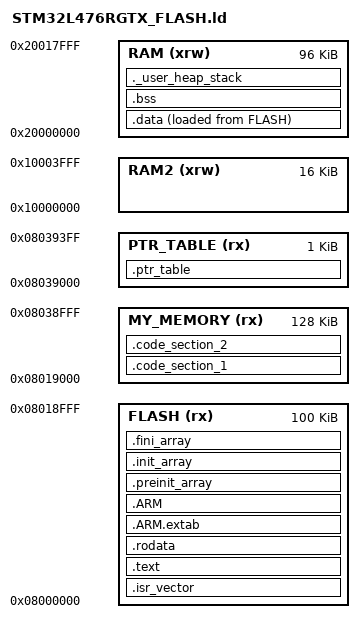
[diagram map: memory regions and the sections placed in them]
/*
******************************************************************************
**
** @file        : LinkerScript.ld
**
** @author      : Auto-generated by STM32CubeIDE
**
**  Abstract    : Linker script for NUCLEO-L476RG Board embedding STM32L476RGTx Device from stm32l4 series
**                      1024Kbytes FLASH
**                      96Kbytes RAM
**                      32Kbytes RAM2
**
**                Set heap size, stack size and stack location according
**                to application requirements.
**
**                Set memory bank area and size if external memory is used
**
**  Target      : STMicroelectronics STM32
**
**  Distribution: The file is distributed as is, without any warranty
**                of any kind.
**
******************************************************************************
** @attention
**
** Copyright (c) 2022 STMicroelectronics.
** All rights reserved.
**
** This software is licensed under terms that can be found in the LICENSE file
** in the root directory of this software component.
** If no LICENSE file comes with this software, it is provided AS-IS.
**
******************************************************************************
*/

/* Entry Point */
ENTRY(Reset_Handler)

/* Highest address of the user mode stack */
_estack = ORIGIN(RAM) + LENGTH(RAM); /* end of "RAM" Ram type memory */

_Min_Heap_Size = 0x200 ; /* required amount of heap */
_Min_Stack_Size = 0x400 ; /* required amount of stack */

/* Memories definition */
MEMORY
{
  RAM    (xrw)    	: ORIGIN = 0x20000000,  LENGTH = 96K
  RAM2    (xrw)    	: ORIGIN = 0x10000000,  LENGTH = 16K
  FLASH    (rx)    	: ORIGIN = 0x8000000,   LENGTH = 100K
  MY_MEMORY (rx)  	: ORIGIN = 0x8019000,	LENGTH = 128k
  PTR_TABLE (rx)  	: ORIGIN = 0x8039000,	LENGTH = 1k
}

/* Sections */
SECTIONS
{
  /* The startup code into "FLASH" Rom type memory */
  .isr_vector :
  {
    . = ALIGN(4);
    KEEP(*(.isr_vector)) /* Startup code */
    . = ALIGN(4);
  } >FLASH

  /* The program code and other data into "FLASH" Rom type memory */
  .text :
  {
    . = ALIGN(4);
    *(.text)           /* .text sections (code) */
    *(.text*)          /* .text* sections (code) */
    *(.glue_7)         /* glue arm to thumb code */
    *(.glue_7t)        /* glue thumb to arm code */
    *(.eh_frame)

    KEEP (*(.init))
    KEEP (*(.fini))

    . = ALIGN(4);
    _etext = .;        /* define a global symbols at end of code */
  } >FLASH
  
    /* LUT for function pointers */
  .ptr_table :
  {
  	__ptr_table_start__ = .;
	. = ALIGN(4);
	lut_func_ptr_1 = .;
	lut_func_ptr_2 = .;
	lut_func_ptr_3 = .;
	lut_func_ptr_4 = .;
	. = ALIGN(4);
  	__ptr_table_end__ = .;
  } >PTR_TABLE

  /* Check if PTR_TABLE usage exceeds PTR_TABLE size */
  ASSERT( LENGTH(PTR_TABLE) >= (__ptr_table_end__ - __ptr_table_start__), "PTR_TABLE memory overflowed !")
  
  .code_section_1 :
  {
    . = ALIGN(4);
	__mysection_start__ = .;
	/* function 1 copy location */
	lut_func_ptr_1 = .;
	*(.function_1*)
	*(.section_1*)
	some_var = .;
	. = ALIGN(4);
  } >MY_MEMORY
  
  .code_section_2 :
  {
    . = ALIGN(4);
    /* function 2 copy location */
	lut_func_ptr_2 = .;
	*(.function_2*)
	*(.section_2*)
	another_var = .;
	. = ALIGN(4);
	__mysection_end__ = .;
  } >MY_MEMORY

  /* Check if MY_MEMORY usage exceeds MY_MEMORY size */
  ASSERT( LENGTH(MY_MEMORY) >= (__mysection_end__ - __mysection_start__), "MY_MEMORY memory overflowed !")

  /* Constant data into "FLASH" Rom type memory */
  .rodata :
  {
    . = ALIGN(4);
    *(.rodata)         /* .rodata sections (constants, strings, etc.) */
    *(.rodata*)        /* .rodata* sections (constants, strings, etc.) */
    . = ALIGN(4);
  } >FLASH

  .ARM.extab   : {
    . = ALIGN(4);
    *(.ARM.extab* .gnu.linkonce.armextab.*)
    . = ALIGN(4);
  } >FLASH

  .ARM : {
    . = ALIGN(4);
    __exidx_start = .;
    *(.ARM.exidx*)
    __exidx_end = .;
    . = ALIGN(4);
  } >FLASH

  .preinit_array     :
  {
    . = ALIGN(4);
    PROVIDE_HIDDEN (__preinit_array_start = .);
    KEEP (*(.preinit_array*))
    PROVIDE_HIDDEN (__preinit_array_end = .);
    . = ALIGN(4);
  } >FLASH

  .init_array :
  {
    . = ALIGN(4);
    PROVIDE_HIDDEN (__init_array_start = .);
    KEEP (*(SORT(.init_array.*)))
    KEEP (*(.init_array*))
    PROVIDE_HIDDEN (__init_array_end = .);
    . = ALIGN(4);
  } >FLASH

  .fini_array :
  {
    . = ALIGN(4);
    PROVIDE_HIDDEN (__fini_array_start = .);
    KEEP (*(SORT(.fini_array.*)))
    KEEP (*(.fini_array*))
    PROVIDE_HIDDEN (__fini_array_end = .);
    . = ALIGN(4);
  } >FLASH
  
  /* Used by the startup to initialize data */
  _sidata = LOADADDR(.data);

  /* Initialized data sections into "RAM" Ram type memory */
  .data :
  {
    . = ALIGN(4);
    _sdata = .;        /* create a global symbol at data start */
    *(.data)           /* .data sections */
    *(.data*)          /* .data* sections */
    *(.RamFunc)        /* .RamFunc sections */
    *(.RamFunc*)       /* .RamFunc* sections */

    . = ALIGN(4);
    _edata = .;        /* define a global symbol at data end */

  } >RAM AT> FLASH

  /* Uninitialized data section into "RAM" Ram type memory */
  . = ALIGN(4);
  .bss :
  {
    /* This is used by the startup in order to initialize the .bss section */
    _sbss = .;         /* define a global symbol at bss start */
    __bss_start__ = _sbss;
    *(.bss)
    *(.bss*)
    *(COMMON)

    . = ALIGN(4);
    _ebss = .;         /* define a global symbol at bss end */
    __bss_end__ = _ebss;
  } >RAM

  /* User_heap_stack section, used to check that there is enough "RAM" Ram  type memory left */
  ._user_heap_stack :
  {
    . = ALIGN(8);
    PROVIDE ( end = . );
    PROVIDE ( _end = . );
    . = . + _Min_Heap_Size;
    . = . + _Min_Stack_Size;
    . = ALIGN(8);
  } >RAM

  /* Remove information from the compiler libraries */
  /DISCARD/ :
  {
    libc.a ( * )
    libm.a ( * )
    libgcc.a ( * )
  }

  .ARM.attributes 0 : { *(.ARM.attributes) }
}
